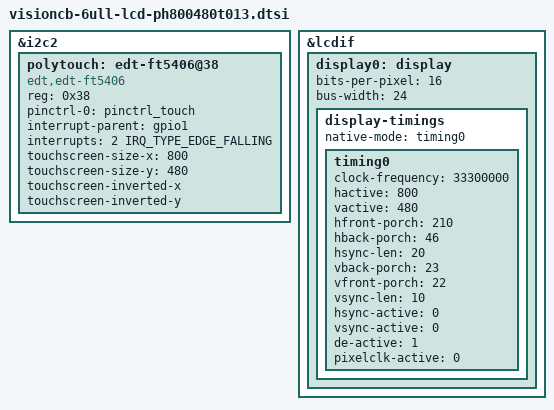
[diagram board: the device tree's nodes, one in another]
// SPDX-License-Identifier: GPL-2.0-or-later
/*
 * Copyright (C) 2020-2023 SoMLabs
 */

&i2c2 {
        polytouch: edt-ft5406@38 {
                status = "okay";
                compatible = "edt,edt-ft5406", "edt,edt-ft5x06";
                reg = <0x38>;
                pinctrl-names = "default";
                pinctrl-0 = <&pinctrl_touch>;
                interrupt-parent = <&gpio1>;
                interrupts = <2 IRQ_TYPE_EDGE_FALLING>;
                touchscreen-size-x = <800>;
                touchscreen-size-y = <480>;
                touchscreen-inverted-x;
                touchscreen-inverted-y;
        };
};

&lcdif {
        display0: display {
                bits-per-pixel = <16>;
                bus-width = <24>;

                display-timings {
                        native-mode = <&timing0>;
                        timing0: timing0 {
                                clock-frequency = <33300000>;
                                hactive = <800>;
                                vactive = <480>;
                                hfront-porch = <210>;
                                hback-porch = <46>;
                                hsync-len = <20>;
                                vback-porch = <23>;
                                vfront-porch = <22>;
                                vsync-len = <10>;

                                hsync-active = <0>;
                                vsync-active = <0>;
                                de-active = <1>;
                                pixelclk-active = <0>;
                        };
                };
        };
};
